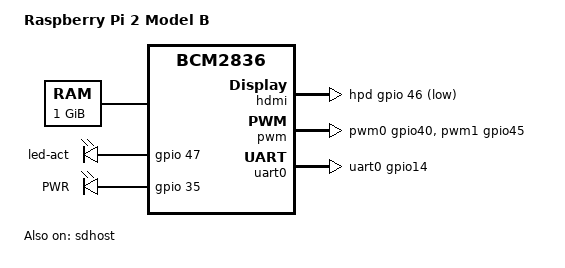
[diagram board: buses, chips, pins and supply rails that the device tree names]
// SPDX-License-Identifier: GPL-2.0
/dts-v1/;
#include "bcm2836.dtsi"
#include "bcm2836-rpi.dtsi"
#include "bcm283x-rpi-smsc9514.dtsi"
#include "bcm283x-rpi-usb-host.dtsi"

/ {
	compatible = "raspberrypi,2-model-b", "brcm,bcm2836";
	model = "Raspberry Pi 2 Model B";

	memory@0 {
		device_type = "memory";
		reg = <0 0x40000000>;
	};

	leds {
		led-act {
			gpios = <&gpio 47 GPIO_ACTIVE_HIGH>;
		};

		led-pwr {
			label = "PWR";
			gpios = <&gpio 35 GPIO_ACTIVE_HIGH>;
			default-state = "keep";
			linux,default-trigger = "default-on";
		};
	};
};

&gpio {
	/*
	 * Taken from rpi_SCH_2b_1p2_reduced.pdf and
	 * the official GPU firmware DT blob.
	 *
	 * Legend:
	 * "NC" = not connected (no rail from the SoC)
	 * "FOO" = GPIO line named "FOO" on the schematic
	 * "FOO_N" = GPIO line named "FOO" on schematic, active low
	 */
	gpio-line-names = "ID_SDA",
			  "ID_SCL",
			  "SDA1",
			  "SCL1",
			  "GPIO_GCLK",
			  "GPIO5",
			  "GPIO6",
			  "SPI_CE1_N",
			  "SPI_CE0_N",
			  "SPI_MISO",
			  "SPI_MOSI",
			  "SPI_SCLK",
			  "GPIO12",
			  "GPIO13",
			  /* Serial port */
			  "TXD0",
			  "RXD0",
			  "GPIO16",
			  "GPIO17",
			  "GPIO18",
			  "GPIO19",
			  "GPIO20",
			  "GPIO21",
			  "GPIO22",
			  "GPIO23",
			  "GPIO24",
			  "GPIO25",
			  "GPIO26",
			  "GPIO27",
			  "SDA0",
			  "SCL0",
			  "", /* GPIO30 */
			  "LAN_RUN",
			  "CAM_GPIO1",
			  "", /* GPIO33 */
			  "", /* GPIO34 */
			  "PWR_LOW_N",
			  "", /* GPIO36 */
			  "", /* GPIO37 */
			  "USB_LIMIT",
			  "", /* GPIO39 */
			  "PWM0_OUT",
			  "CAM_GPIO0",
			  "SMPS_SCL",
			  "SMPS_SDA",
			  "ETHCLK",
			  "PWM1_OUT",
			  "HDMI_HPD_N",
			  "STATUS_LED",
			  /* Used by SD Card */
			  "SD_CLK_R",
			  "SD_CMD_R",
			  "SD_DATA0_R",
			  "SD_DATA1_R",
			  "SD_DATA2_R",
			  "SD_DATA3_R";

	pinctrl-0 = <&gpioout &alt0 &i2s_alt0>;

	/* I2S interface */
	i2s_alt0: i2s_alt0 {
		brcm,pins = <18 19 20 21>;
		brcm,function = <BCM2835_FSEL_ALT0>;
	};
};

&hdmi {
	hpd-gpios = <&gpio 46 GPIO_ACTIVE_LOW>;
	power-domains = <&power RPI_POWER_DOMAIN_HDMI>;
	status = "okay";
};

&pwm {
	pinctrl-names = "default";
	pinctrl-0 = <&pwm0_gpio40 &pwm1_gpio45>;
	status = "okay";
};

&sdhost {
	pinctrl-names = "default";
	pinctrl-0 = <&sdhost_gpio48>;
	bus-width = <4>;
	status = "okay";
};

&uart0 {
	pinctrl-names = "default";
	pinctrl-0 = <&uart0_gpio14>;
	status = "okay";
};
